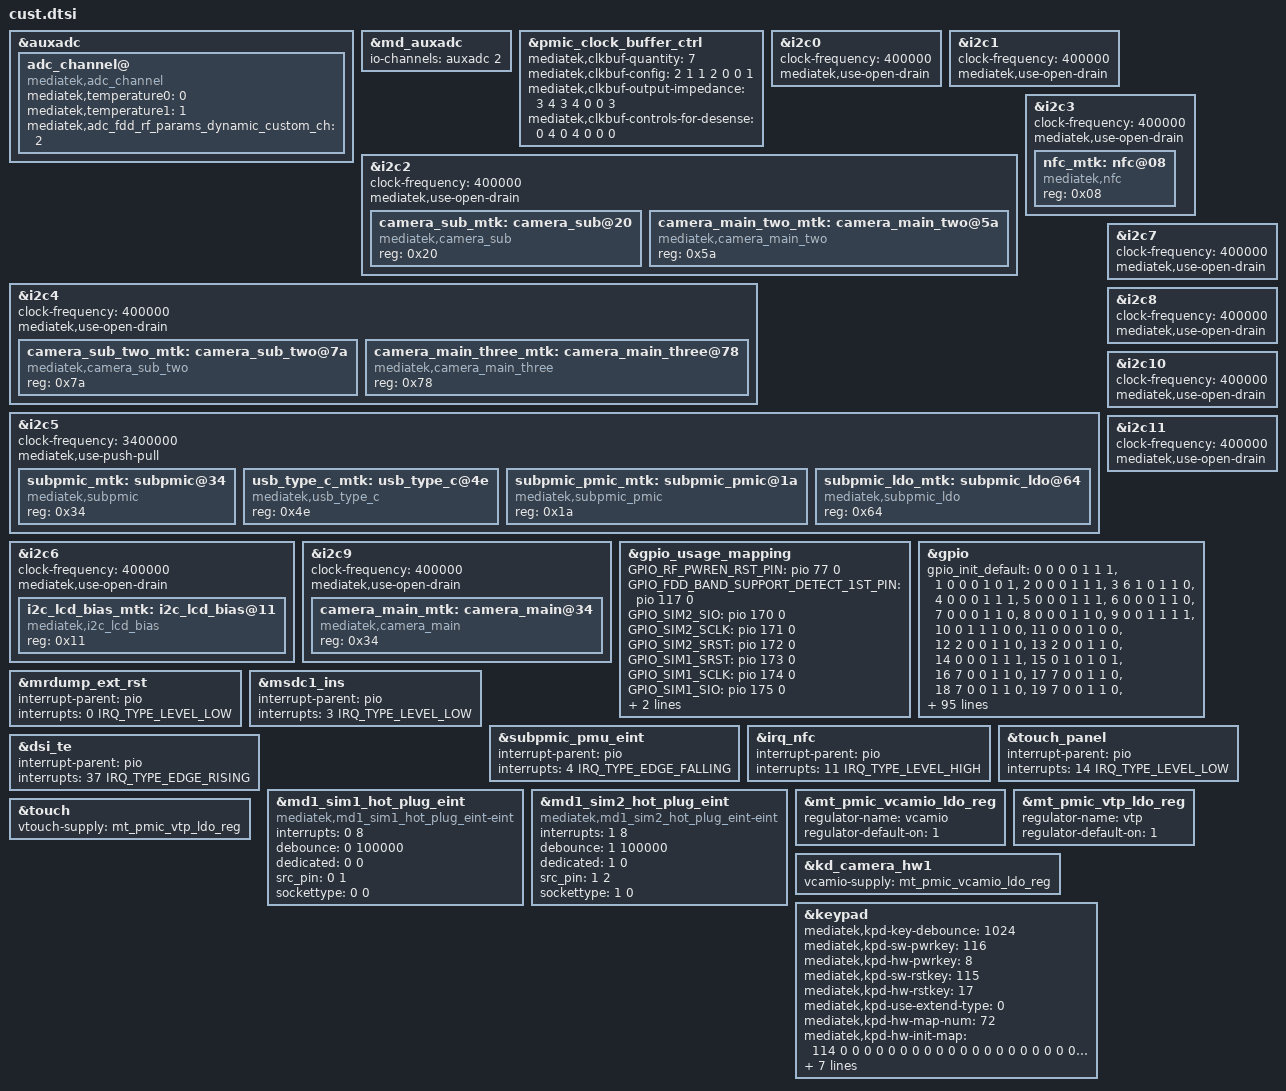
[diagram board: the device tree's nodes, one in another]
/*
 * Generated by MTK SP DrvGen Version: 3.5.160809 for MT6877.
 * 2023-07-07 23:24:14
 * Do Not Modify The File.
 * Copyright Mediatek Inc. (c) 2016.
*/

/*************************
 * ADC DTSI File
*************************/

&auxadc {
	adc_channel@ {
		compatible = "mediatek,adc_channel";
		mediatek,temperature0 = <0>;
		mediatek,temperature1 = <1>;
		mediatek,adc_fdd_rf_params_dynamic_custom_ch = <2>;
		status = "okay";
	};
};
&md_auxadc {
	io-channels = <&auxadc 2>;
};


/*************************
 * CLK_BUF DTSI File
*************************/

&pmic_clock_buffer_ctrl {
	mediatek,clkbuf-quantity = <7>;
	mediatek,clkbuf-config = <2 1 1 2 0 0 1>;
	mediatek,clkbuf-output-impedance = <3 4 3 4 0 0 3>;
	mediatek,clkbuf-controls-for-desense = <0 4 0 4 0 0 0>;
	status = "okay";
};


/*************************
 * I2C DTSI File
*************************/

&i2c0 {
	#address-cells = <1>;
	#size-cells = <0>;
	clock-frequency = <400000>;
	mediatek,use-open-drain;
};

&i2c1 {
	#address-cells = <1>;
	#size-cells = <0>;
	clock-frequency = <400000>;
	mediatek,use-open-drain;
};

&i2c2 {
	#address-cells = <1>;
	#size-cells = <0>;
	clock-frequency = <400000>;
	mediatek,use-open-drain;
	camera_sub_mtk:camera_sub@20 {
		compatible = "mediatek,camera_sub";
		reg = <0x20>;
		status = "okay";
	};

	camera_main_two_mtk:camera_main_two@5a {
		compatible = "mediatek,camera_main_two";
		reg = <0x5a>;
		status = "okay";
	};

};

&i2c3 {
	#address-cells = <1>;
	#size-cells = <0>;
	clock-frequency = <400000>;
	mediatek,use-open-drain;
	nfc_mtk:nfc@08 {
		compatible = "mediatek,nfc";
		reg = <0x08>;
		status = "okay";
	};

};

&i2c4 {
	#address-cells = <1>;
	#size-cells = <0>;
	clock-frequency = <400000>;
	mediatek,use-open-drain;
	camera_sub_two_mtk:camera_sub_two@7a {
		compatible = "mediatek,camera_sub_two";
		reg = <0x7a>;
		status = "okay";
	};

	camera_main_three_mtk:camera_main_three@78 {
		compatible = "mediatek,camera_main_three";
		reg = <0x78>;
		status = "okay";
	};

};

&i2c5 {
	#address-cells = <1>;
	#size-cells = <0>;
	clock-frequency = <3400000>;
	mediatek,use-push-pull;
	subpmic_mtk:subpmic@34 {
		compatible = "mediatek,subpmic";
		reg = <0x34>;
		status = "okay";
	};

	usb_type_c_mtk:usb_type_c@4e {
		compatible = "mediatek,usb_type_c";
		reg = <0x4e>;
		status = "okay";
	};

	subpmic_pmic_mtk:subpmic_pmic@1a {
		compatible = "mediatek,subpmic_pmic";
		reg = <0x1a>;
		status = "okay";
	};

	subpmic_ldo_mtk:subpmic_ldo@64 {
		compatible = "mediatek,subpmic_ldo";
		reg = <0x64>;
		status = "okay";
	};

};

&i2c6 {
	#address-cells = <1>;
	#size-cells = <0>;
	clock-frequency = <400000>;
	mediatek,use-open-drain;
	i2c_lcd_bias_mtk:i2c_lcd_bias@11 {
		compatible = "mediatek,i2c_lcd_bias";
		reg = <0x11>;
		status = "okay";
	};

};

&i2c7 {
	#address-cells = <1>;
	#size-cells = <0>;
	clock-frequency = <400000>;
	mediatek,use-open-drain;
};

&i2c8 {
	#address-cells = <1>;
	#size-cells = <0>;
	clock-frequency = <400000>;
	mediatek,use-open-drain;
};

&i2c9 {
	#address-cells = <1>;
	#size-cells = <0>;
	clock-frequency = <400000>;
	mediatek,use-open-drain;
	camera_main_mtk:camera_main@34 {
		compatible = "mediatek,camera_main";
		reg = <0x34>;
		status = "okay";
	};

};

&i2c10 {
	#address-cells = <1>;
	#size-cells = <0>;
	clock-frequency = <400000>;
	mediatek,use-open-drain;
};

&i2c11 {
	#address-cells = <1>;
	#size-cells = <0>;
	clock-frequency = <400000>;
	mediatek,use-open-drain;
};



/*************************
 * GPIO DTSI File
*************************/

&gpio_usage_mapping {
	GPIO_RF_PWREN_RST_PIN = <&pio 77 0>;
	GPIO_FDD_BAND_SUPPORT_DETECT_1ST_PIN = <&pio 117 0>;
	GPIO_SIM2_SIO = <&pio 170 0>;
	GPIO_SIM2_SCLK = <&pio 171 0>;
	GPIO_SIM2_SRST = <&pio 172 0>;
	GPIO_SIM1_SRST = <&pio 173 0>;
	GPIO_SIM1_SCLK = <&pio 174 0>;
	GPIO_SIM1_SIO = <&pio 175 0>;
	GPIO_SIM1_HOT_PLUG = <&pio 176 0>;
	GPIO_SIM2_HOT_PLUG = <&pio 177 0>;
};

&gpio{
	gpio_init_default = <0 0 0 0 1 1 1>,
		<1 0 0 0 1 0 1>,
		<2 0 0 0 1 1 1>,
		<3 6 1 0 1 1 0>,
		<4 0 0 0 1 1 1>,
		<5 0 0 0 1 1 1>,
		<6 0 0 0 1 1 0>,
		<7 0 0 0 1 1 0>,
		<8 0 0 0 1 1 0>,
		<9 0 0 1 1 1 1>,
		<10 0 1 1 1 0 0>,
		<11 0 0 0 1 0 0>,
		<12 2 0 0 1 1 0>,
		<13 2 0 0 1 1 0>,
		<14 0 0 0 1 1 1>,
		<15 0 1 0 1 0 1>,
		<16 7 0 0 1 1 0>,
		<17 7 0 0 1 1 0>,
		<18 7 0 0 1 1 0>,
		<19 7 0 0 1 1 0>,
		<20 7 0 0 0 0 0>,
		<21 0 1 0 1 0 0>,
		<22 0 0 0 1 0 0>,
		<23 7 0 0 1 1 0>,
		<24 1 0 0 0 0 0>,
		<25 1 0 0 0 0 0>,
		<26 1 0 0 1 1 0>,
		<27 1 0 0 0 0 0>,
		<28 1 0 0 1 1 0>,
		<29 1 0 0 1 1 0>,
		<30 0 1 0 1 0 0>,
		<31 0 1 1 1 0 0>,
		<32 1 0 0 1 1 0>,
		<33 1 0 0 1 1 0>,
		<34 1 0 0 1 1 0>,
		<35 1 0 0 1 1 0>,
		<36 3 0 0 1 1 1>,
		<37 3 0 0 1 1 1>,
		<38 1 0 0 1 1 1>,
		<39 1 0 0 1 0 1>,
		<40 0 1 0 1 0 1>,
		<41 1 0 0 0 0 1>,
		<42 1 0 0 0 0 1>,
		<43 1 0 0 1 0 1>,
		<44 1 0 0 1 0 1>,
		<45 1 0 0 1 1 1>,
		<46 1 0 0 0 0 0>,
		<47 1 0 0 0 0 0>,
		<48 1 0 0 0 0 0>,
		<49 1 0 0 0 0 0>,
		<50 1 0 0 1 0 0>,
		<51 1 0 0 1 0 0>,
		<52 1 0 0 1 0 0>,
		<53 1 0 0 1 0 0>,
		<54 1 0 0 1 0 1>,
		<55 1 0 0 1 0 0>,
		<56 1 0 0 1 0 0>,
		<57 1 0 0 1 0 0>,
		<58 1 0 0 1 0 0>,
		<59 1 0 0 1 0 0>,
		<60 1 0 0 0 0 1>,
		<61 1 0 0 0 0 1>,
		<62 2 0 0 1 1 1>,
		<63 2 0 0 1 1 1>,
		<64 1 0 0 1 1 1>,
		<65 1 0 0 1 1 1>,
		<66 1 0 0 1 0 1>,
		<67 1 0 0 1 0 1>,
		<68 1 0 0 0 0 0>,
		<69 1 0 0 1 0 0>,
		<70 1 0 0 1 0 1>,
		<71 1 0 0 0 0 1>,
		<72 1 0 0 0 0 1>,
		<73 1 0 0 0 0 1>,
		<74 1 0 0 0 0 1>,
		<75 1 0 0 0 0 1>,
		<76 1 0 0 0 0 1>,
		<77 0 1 1 1 0 1>,
		<78 1 0 0 0 0 1>,
		<79 1 0 0 0 0 1>,
		<80 1 0 0 0 0 1>,
		<81 1 0 0 0 0 1>,
		<82 1 0 0 0 0 0>,
		<83 1 0 0 1 0 0>,
		<84 1 0 0 0 0 0>,
		<85 1 0 0 1 0 0>,
		<86 1 0 0 1 0 1>,
		<87 1 0 0 0 0 1>,
		<88 1 0 0 0 0 1>,
		<89 1 0 0 0 0 1>,
		<90 1 0 0 0 0 1>,
		<91 1 0 0 0 0 1>,
		<92 1 0 0 0 0 1>,
		<93 1 0 0 0 0 1>,
		<94 1 0 0 0 0 1>,
		<95 1 0 0 0 0 1>,
		<96 1 0 0 0 0 1>,
		<97 1 0 0 0 0 1>,
		<98 1 0 0 0 0 0>,
		<99 0 0 0 0 0 0>,
		<100 1 0 0 1 0 1>,
		<101 1 0 0 0 0 0>,
		<102 0 0 0 1 1 1>,
		<103 1 0 0 1 1 0>,
		<104 1 0 0 1 1 0>,
		<105 1 0 0 1 1 1>,
		<106 1 0 0 1 1 0>,
		<107 1 0 0 0 0 1>,
		<108 0 1 0 1 0 1>,
		<109 0 1 0 1 0 0>,
		<110 0 1 0 1 0 0>,
		<111 0 1 0 1 0 0>,
		<112 1 0 0 1 1 1>,
		<113 0 0 0 1 1 0>,
		<114 0 0 0 1 1 0>,
		<115 1 0 0 1 0 0>,
		<116 1 0 0 1 1 1>,
		<117 0 0 0 1 1 1>,
		<118 0 1 1 1 0 1>,
		<119 0 0 0 1 1 1>,
		<120 0 0 0 1 1 1>,
		<121 0 0 0 1 1 1>,
		<122 2 0 0 1 0 0>,
		<123 2 0 0 1 0 0>,
		<124 2 0 0 1 0 0>,
		<125 2 0 0 1 0 0>,
		<126 2 0 0 1 0 0>,
		<127 2 0 0 1 0 0>,
		<128 2 0 0 1 1 1>,
		<129 2 0 0 1 0 1>,
		<130 2 0 0 1 1 1>,
		<131 2 0 0 1 1 1>,
		<132 1 0 0 1 1 1>,
		<133 1 0 0 1 1 1>,
		<134 1 0 0 1 1 1>,
		<135 1 0 0 1 1 1>,
		<136 2 0 0 1 1 1>,
		<137 2 0 0 1 1 1>,
		<138 0 1 1 1 0 1>,
		<139 4 0 0 1 1 0>,
		<140 0 1 0 1 0 1>,
		<141 0 1 0 1 0 1>,
		<142 0 1 0 1 0 0>,
		<143 1 0 0 1 1 1>,
		<144 1 0 0 1 1 1>,
		<145 1 0 0 1 1 1>,
		<146 1 0 0 1 1 1>,
		<147 1 0 0 1 1 1>,
		<148 1 0 0 1 1 1>,
		<149 1 0 0 1 1 0>,
		<150 1 0 0 1 1 0>,
		<151 1 0 0 1 1 0>,
		<152 1 0 0 1 1 0>,
		<153 0 0 0 1 1 0>,
		<154 0 1 0 1 0 0>,
		<155 0 1 0 1 0 0>,
		<156 0 1 0 1 0 0>,
		<157 0 1 0 1 0 0>,
		<158 0 1 0 1 0 0>,
		<159 0 1 0 1 0 0>,
		<160 0 0 0 1 1 0>,
		<161 0 1 0 1 0 0>,
		<162 0 1 1 1 0 0>,
		<163 0 0 0 1 1 1>,
		<164 1 0 0 1 1 0>,
		<165 1 0 0 0 0 0>,
		<166 1 0 0 1 1 0>,
		<167 0 1 0 1 0 1>,
		<168 0 1 0 1 0 1>,
		<169 0 1 0 1 0 0>,
		<170 1 0 0 1 1 1>,
		<171 1 0 0 0 0 1>,
		<172 1 0 0 0 0 1>,
		<173 1 0 0 0 0 1>,
		<174 1 0 0 0 0 1>,
		<175 1 0 0 1 1 1>,
		<176 1 0 0 1 1 1>,
		<177 1 0 0 1 1 1>,
		<178 1 0 0 1 0 0>,
		<179 1 0 0 1 0 0>,
		<180 1 0 0 1 1 1>,
		<181 1 0 0 1 1 1>,
		<182 1 0 0 0 0 0>,
		<183 1 0 0 1 0 0>,
		<184 1 0 0 0 0 0>,
		<185 1 1 0 0 0 0>,
		<186 1 0 0 1 1 1>,
		<187 1 0 0 1 1 1>,
		<188 0 1 0 1 0 0>,
		<189 0 1 0 1 0 0>,
		<190 1 0 0 1 1 0>,
		<191 0 1 0 1 0 0>,
		<192 1 0 0 1 1 0>,
		<193 0 0 0 1 1 0>,
		<194 0 0 0 1 1 0>,
		<195 0 0 0 1 1 0>,
		<196 0 0 0 1 0 0>,
		<197 0 0 0 1 0 0>,
		<198 0 0 0 1 0 0>,
		<199 0 0 0 1 0 0>,
		<200 0 0 0 1 0 0>,
		<201 0 0 0 1 0 0>,
		<202 0 0 0 1 0 0>,
		<203 0 0 0 1 0 0>,
		<204 0 0 0 1 0 0>,
		<205 0 0 0 1 0 0>,
		<206 0 0 0 1 0 0>,
		<207 0 0 0 1 0 0>,
		<208 0 0 0 1 0 0>;
};


/*************************
 * EINT DTSI File
*************************/

#include <dt-bindings/interrupt-controller/irq.h>
#include <dt-bindings/interrupt-controller/arm-gic.h>

&mrdump_ext_rst {
	interrupt-parent = <&pio>;
	interrupts = <0 IRQ_TYPE_LEVEL_LOW>;
	status = "okay";
};

&msdc1_ins {
	interrupt-parent = <&pio>;
	interrupts = <3 IRQ_TYPE_LEVEL_LOW>;
	status = "okay";
};

&subpmic_pmu_eint {
	interrupt-parent = <&pio>;
	interrupts = <4 IRQ_TYPE_EDGE_FALLING>;
	status = "okay";
};

&irq_nfc {
	interrupt-parent = <&pio>;
	interrupts = <11 IRQ_TYPE_LEVEL_HIGH>;
	status = "okay";
};

&touch_panel {
	interrupt-parent = <&pio>;
	interrupts = <14 IRQ_TYPE_LEVEL_LOW>;
	status = "okay";
};

&dsi_te {
	interrupt-parent = <&pio>;
	interrupts = <37 IRQ_TYPE_EDGE_RISING>;
	status = "okay";
};



/*************************
 * MD1_EINT DTSI File
*************************/

&md1_sim1_hot_plug_eint {
	compatible = "mediatek,md1_sim1_hot_plug_eint-eint";
	interrupts = <0 8>;
	debounce = <0 100000>;
	dedicated = <0 0>;
	src_pin = <0 1>;
	sockettype = <0 0>;
	status = "okay";
};

&md1_sim2_hot_plug_eint {
	compatible = "mediatek,md1_sim2_hot_plug_eint-eint";
	interrupts = <1 8>;
	debounce = <1 100000>;
	dedicated = <1 0>;
	src_pin = <1 2>;
	sockettype = <1 0>;
	status = "okay";
};



/*************************
 * PMIC DTSI File
*************************/

&mt_pmic_vcamio_ldo_reg {
	regulator-name = "vcamio";
	regulator-default-on = <1>; /* 0:skip, 1: off, 2:on */
	status = "okay";
};
&mt_pmic_vtp_ldo_reg {
	regulator-name = "vtp";
	regulator-default-on = <1>; /* 0:skip, 1: off, 2:on */
	status = "okay";
};

&kd_camera_hw1 {
	vcamio-supply = <&mt_pmic_vcamio_ldo_reg>;
	status = "okay";
};

&touch {
	vtouch-supply = <&mt_pmic_vtp_ldo_reg>;
	status = "okay";
};


/*************************
 * POWER DTSI File
*************************/



/*************************
 * KPD DTSI File
*************************/

&keypad {
	mediatek,kpd-key-debounce = <1024>;
	mediatek,kpd-sw-pwrkey = <116>;
	mediatek,kpd-hw-pwrkey = <8>;
	mediatek,kpd-sw-rstkey  = <115>;
	mediatek,kpd-hw-rstkey = <17>;
	mediatek,kpd-use-extend-type = <0>;
	/*HW Keycode [0~71] -> Linux Keycode*/
	mediatek,kpd-hw-map-num = <72>;
	mediatek,kpd-hw-init-map = <114 0 0 0 0 0 0 0 0 0 0 0 0 0 0 0 0 0 0 0 0 0 0 0 0 0 0 0 0 0 0 0 0 0 0 0 0 0 0 0 0 0 0 0 0 0 0 0 0 0 0 0 0 0 0 0 0 0 0 0 0 0 0 0 0 0 0 0 0 0 0 0 >;
	mediatek,kpd-pwrkey-eint-gpio = <0>;
	mediatek,kpd-pwkey-gpio-din  = <0>;
	mediatek,kpd-hw-dl-key0 = <17>;
	mediatek,kpd-hw-dl-key1 = <0>;
	mediatek,kpd-hw-dl-key2 = <8>;
	mediatek,kpd-hw-recovery-key = <17>;
	mediatek,kpd-hw-factory-key = <0>;
	status = "okay";
};


